AUTOSAR XML (schema 00046)
package /jmc_auto/Functional/ControlApplication
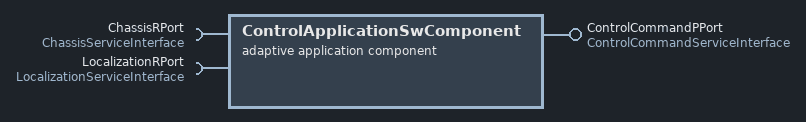
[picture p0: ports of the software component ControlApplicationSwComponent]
  adaptive application sw component type ControlApplicationSwComponent
    require port ChassisRPort: required-interface=ChassisServiceInterface
    provide port ControlCommandPPort: provided-interface=ControlCommandServiceInterface
    require port LocalizationRPort: required-interface=LocalizationServiceInterface
package /jmc_auto/Functional/ControlExecutable
  executable ControlExecutable
    root sw component prototype ControlRootSwComponent: application-type=ControlApplicationSwComponent
